VERSION ""

NS_ :

BS_:

BU_:

BO_ 32 state: 1 Vector__XXX
 SG_ system_state : 0|8@1+ (1,0) [0|255] "" Vector__XXX

BO_ 64 command_servo_1: 2 Vector__XXX
 SG_ command_servo_1_pmw : 0|16@1+ (1,0) [500|2500] "us" Vector__XXX

BO_ 96 command_servo_2: 2 Vector__XXX
 SG_ command_servo_2_pmw : 0|16@1+ (1,0) [500|2500] "us" Vector__XXX

BO_ 128 command_servo_3: 2 Vector__XXX
 SG_ command_servo_3_pmw : 0|16@1+ (1,0) [500|2500] "us" Vector__XXX

BO_ 160 command_servo_4: 2 Vector__XXX
 SG_ command_servo_4_pmw : 0|16@1+ (1,0) [500|2500] "us" Vector__XXX

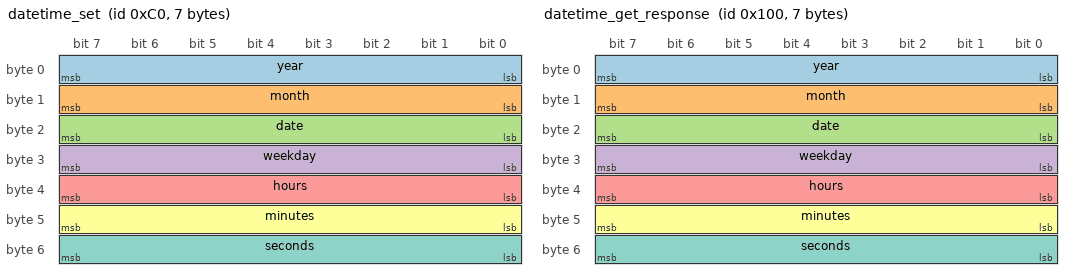
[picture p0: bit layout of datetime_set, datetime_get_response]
BO_ 192 datetime_set: 7 Vector__XXX
 SG_ year : 0|8@1+ (1,0) [0|99] "year" Vector__XXX
 SG_ month : 8|8@1+ (1,0) [1|12] "month" Vector__XXX
 SG_ date : 16|8@1+ (1,0) [1|31] "day" Vector__XXX
 SG_ weekday : 24|8@1+ (1,0) [1|7] "weekday" Vector__XXX
 SG_ hours : 32|8@1+ (1,0) [0|23] "hour" Vector__XXX
 SG_ minutes : 40|8@1+ (1,0) [0|59] "min" Vector__XXX
 SG_ seconds : 48|8@1+ (1,0) [0|59] "sec" Vector__XXX

BO_ 224 datetime_get: 0 Vector__XXX

BO_ 256 datetime_get_response: 7 Vector__XXX
 SG_ year : 0|8@1+ (1,0) [0|99] "year" Vector__XXX
 SG_ month : 8|8@1+ (1,0) [1|12] "month" Vector__XXX
 SG_ date : 16|8@1+ (1,0) [1|31] "day" Vector__XXX
 SG_ weekday : 24|8@1+ (1,0) [1|7] "weekday" Vector__XXX
 SG_ hours : 32|8@1+ (1,0) [0|23] "hour" Vector__XXX
 SG_ minutes : 40|8@1+ (1,0) [0|59] "min" Vector__XXX
 SG_ seconds : 48|8@1+ (1,0) [0|59] "sec" Vector__XXX

CM_ BO_ 32 "State machine info";
BA_DEF_  "BusType" STRING ;
BA_DEF_DEF_  "BusType" "CAN";
